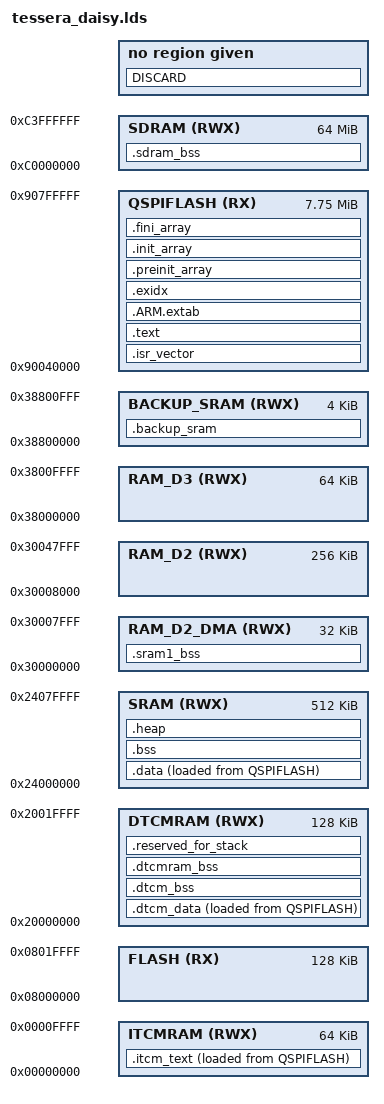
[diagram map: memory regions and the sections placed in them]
/* SPDX-License-Identifier: MIT (libDaisy, LICENSES/MIT-libDaisy.txt); Tessera's placements: Copyright (C) 2026 Theo Dainis */
/* Andamento: the Daisy Seed's memory map for Tessera, BOOT_QSPI.
 *
 * libDaisy's core/STM32H750IB_qspi.lds (libDaisy 1289a00, MIT; its own header follows), with Tessera's audio path
 * placed in the H750's fast memories. Everything else is as libDaisy has it: code in the 8 MB QSPI flash (read
 * through the cache), data in the 512 KB AXI SRAM, DMA buffers in RAM_D2_DMA (not cached), the stack at the top
 * of DTCM.
 *
 *   ITCM  64 KB  .itcm_text  the code that runs for every sample: what the FM-1 build keeps in its RAM
 *                            (.audio_text, .dsp_text), the mixer and the engines' render loops, as many as fit
 *                            (itcm_pick.py chooses, at build time). No wait states and no cache misses, where
 *                            QSPI code can stall on a miss.
 *   DTCM 128 KB  .dtcm_data  the tables those read for every sample (.dsp_tables and the hot const tables)
 *                .dtcm_bss   the state they write: tracks, effects, FM6's RAM tables, the mix batch, the first
 *                            banks of the audio arena (resources.c), .audio_scratch. The stack shares DTCM, from
 *                            the top down: DTCM_STACK is kept free for it.
 *   AXI SRAM     .bss        as libDaisy, plus the FM-1's .pool (effect lines, big buffers) and .noinit (zeroed:
 *                            nothing is kept across a reset on the Daisy yet)
 *   SDRAM 64 MB  .sdram_bss  nothing of Tessera's yet: long buffers (Beads, samples) go there (DSY_SDRAM_BSS).
 *                            Cached, so a DMA into it needs cache maintenance.
 *
 * ITCM and DTCM are filled by tessera_memory_init (main.cpp) before anything else runs: libDaisy's startup only
 * copies .data and zeroes .bss. Calls between ITCM (0x00000000) and QSPI (0x90000000) are too far for one branch
 * instruction: the linker adds a small veneer for each, which costs a few cycles a call.
 * Names are matched as -fdata-sections spells them (.rodata.NAME, .bss.NAME): a renamed table or array simply
 * stays in the AXI SRAM or QSPI, slower but correct. memcheck.py, run after the link, says where the hot ones are. */

/* Generated by LinkerScriptGenerator [http://visualgdb.com/tools/LinkerScriptGenerator]
 * Target: STM32H750IB
 * The file is provided under the BSD license.
 * yeah okay but i also modified it a lot so like, give me some credit too mr BSD
 */

ENTRY(Reset_Handler)

MEMORY
{
	FLASH       (RX)  : ORIGIN = 0x08000000, LENGTH = 128K
	DTCMRAM     (RWX) : ORIGIN = 0x20000000, LENGTH = 128K
	SRAM        (RWX) : ORIGIN = 0x24000000, LENGTH = 512K
	RAM_D2_DMA  (RWX) : ORIGIN = 0x30000000, LENGTH = 32K
	RAM_D2      (RWX) : ORIGIN = 0x30008000, LENGTH = 256K
	RAM_D3      (RWX) : ORIGIN = 0x38000000, LENGTH = 64K
	BACKUP_SRAM (RWX) : ORIGIN = 0x38800000, LENGTH = 4K
	ITCMRAM     (RWX) : ORIGIN = 0x00000000, LENGTH = 64K
	SDRAM       (RWX) : ORIGIN = 0xc0000000, LENGTH = 64M
	QSPIFLASH   (RX)  : ORIGIN = 0x90040000, LENGTH = 7936K
}

_estack = 0x20020000;
DTCM_STACK = 32K;                       /* kept free at the top of DTCM for the stack (main and interrupts) */

SECTIONS
{
	.isr_vector :
	{
		. = ALIGN(4);
		KEEP(*(.isr_vector))
		. = ALIGN(4);
	} > QSPIFLASH

	/* Tessera's audio path in ITCM, loaded from QSPI and copied at boot. Before .text, whose *(.text*) would
	 * otherwise take these first (the linker places a section by the first rule that matches it) */
	.itcm_text :
	{
		. = ALIGN(8);
		_sitcm_text = .;
		INCLUDE itcm.ld                 /* made at build time by itcm_pick.py: .audio_text, .dsp_text, then the hot functions while they fit */
		. = ALIGN(8);
		_eitcm_text = .;
	} > ITCMRAM AT > QSPIFLASH
	_litcm_text = LOADADDR(.itcm_text);

	/* the tables the audio path reads, copied to DTCM at boot */
	.dtcm_data :
	{
		. = ALIGN(8);
		_sdtcm_data = .;
		*(.dsp_tables*)
		*(.data.tables*)                /* TABLE_RAM (gen_tables.py): the FM-1 keeps these in RAM for the same reason */
		*tessera_core.o(.rodata.SINE .rodata.PITCH_OCT .rodata.ENV_LIN .rodata.LFO_INC .rodata.MICRO_SCALE)
		*tessera_core.o(.rodata.FM6_FREQ_RES .rodata.FM6_MKI_* .rodata.FM6_OPL_* .rodata.FM6_DETUNE .rodata.FM6_FINE)
		*tessera_core.o(.rodata.FM6_GLISS .rodata.FM6_PORTA .rodata.FM6_LFO_INC)
		*tessera_core.o(.rodata.OR_AMOUNT .rodata.OR_ENV_* .rodata.OR_LFO_INC)
		. = ALIGN(8);
		_edtcm_data = .;
	} > DTCMRAM AT > QSPIFLASH
	_ldtcm_data = LOADADDR(.dtcm_data);

	/* the state the audio path writes, zeroed at boot */
	.dtcm_bss (NOLOAD) :
	{
		. = ALIGN(32);
		_sdtcm_bss = .;
		*(.audio_scratch*)
		*tessera_core.o(.bss.trk .bss.fx_state .bss.fx_send_extra_* .bss.batch_*)
		*tessera_core.o(.bss.FM6_SIN .bss.FM6_MKI_LOG .bss.FM6_MKI_EXP .bss.fm6_*)
		*tessera_core.o(.bss.resource_host_low .bss.resource_host_data .bss.resource_host_retained)
		. = ALIGN(8);
		_edtcm_bss = .;
	} > DTCMRAM

	.text :
	{
		. = ALIGN(4);
		_stext = .;

		*(.text)
		*(.text*)
		*(.rodata)
		*(.rodata*)
		*(.glue_7)
		*(.glue_7t)
		KEEP(*(.init))
		KEEP(*(.fini))
		. = ALIGN(4);
		_etext = .;

	} > QSPIFLASH

	.ARM.extab :
	{
		. = ALIGN(4);
		*(.ARM.extab)
		*(.gnu.linkonce.armextab.*)
		. = ALIGN(4);
	} > QSPIFLASH

	.exidx :
	{
		. = ALIGN(4);
		PROVIDE(__exidx_start = .);
		*(.ARM.exidx*)
		. = ALIGN(4);
		PROVIDE(__exidx_end = .);
	} > QSPIFLASH

	.ARM.attributes 0 : { *(.ARM.attributes) }

	.preinit_array :
	{
		PROVIDE_HIDDEN(__preinit_array_start = .);
		KEEP(*(.preinit_array*))
		PROVIDE_HIDDEN(__preinit_array_end = .);
	} > QSPIFLASH

	.init_array :
	{
		PROVIDE_HIDDEN(__init_array_start = .);
		KEEP(*(SORT(.init_array.*)))
		KEEP(*(.init_array*))
		PROVIDE_HIDDEN(__init_array_end = .);
	} > QSPIFLASH

	.fini_array :
	{
		PROVIDE_HIDDEN(__fini_array_start = .);
		KEEP(*(.fini_array*))
		KEEP(*(SORT(.fini_array.*)))
		PROVIDE_HIDDEN(__fini_array_end = .);
	} > QSPIFLASH

	.sram1_bss (NOLOAD) :
	{
		. = ALIGN(4);
		_ssram1_bss = .;

		PROVIDE(__sram1_bss_start__ = _sram1_bss);
		*(.sram1_bss)
		*(.sram1_bss*)
		. = ALIGN(4);
		_esram1_bss = .;

		PROVIDE(__sram1_bss_end__ = _esram1_bss);
	} > RAM_D2_DMA

	.data :
	{
		. = ALIGN(4);
		_sdata = .;

		PROVIDE(__data_start__ = _sdata);
		*(.data)
		*(.data*)
		. = ALIGN(4);
		_edata = .;

		PROVIDE(__data_end__ = _edata);
	} > SRAM AT > QSPIFLASH

	_sidata = LOADADDR(.data);

	.bss (NOLOAD) :
	{
		. = ALIGN(4);
		_sbss = .;

		PROVIDE(__bss_start__ = _sbss);
		*(.bss)
		*(.bss*)
		*(COMMON)
		*(.pool*)
		*(.noinit*)
		. = ALIGN(4);
		_ebss = .;

		PROVIDE(__bss_end__ = _ebss);
	} > SRAM

	.dtcmram_bss (NOLOAD) :
	{
		. = ALIGN(4);
		_sdtcmram_bss = .;

		PROVIDE(__dtcmram_bss_start__ = _sdtcmram_bss);
		*(.dtcmram_bss)
		*(.dtcmram_bss*)
		. = ALIGN(4);
		_edtcmram_bss = .;

		PROVIDE(__dtcmram_bss_end__ = _edtcmram_bss);
	} > DTCMRAM
	ASSERT(_edtcmram_bss <= _estack - DTCM_STACK, "DTCM: the data leaves less than DTCM_STACK for the stack")

	/*
	.sdram_text :
	{
		. = ALIGN(4);
		_ssdram_text = .;

		PROVIDE(__sdram_text_start = _ssdram_text);
		*(.sdram_text)
		*(.sdram_text*)
		. = ALIGN(4);
		_esdram_text = .;

		PROVIDE(__sdram_text_end = _esdram_text);
	} > SDRAM AT >FLASH
	_sisdram_text = LOADADDR(.sdram_text);
	*/

	.sdram_bss (NOLOAD) :
	{
		. = ALIGN(4);
		_ssdram_bss = .;

		PROVIDE(__sdram_bss_start = _ssdram_bss);
		*(.sdram_bss)
		*(.sdram_bss*)
		. = ALIGN(4);
		_esdram_bss = .;

		PROVIDE(__sdram_bss_end = _esdram_bss);
	} > SDRAM

	.backup_sram (NOLOAD) :
	{
		. = ALIGN(4);
		_sbackup_sram = .;

		PROVIDE(__backup_sram_start = _sbackup_sram);
		*(.backup_sram)
		*(.backup_sram*)
		. = ALIGN(4);
		_ebackup_sram = .;

		PROVIDE(__backup_sram_end = _ebackup_sram);
	} > BACKUP_SRAM


    /* .qspiflash_text :
	{
		. = ALIGN(4);
		_sqspiflash_text = .;

		PROVIDE(__qspiflash_text_start = _sqspiflash_text);
		*(.qspiflash_text)
		*(.qspiflash_text*)
		. = ALIGN(4);
		_eqspiflash_text = .;

		PROVIDE(__qspiflash_text_end = _eqspiflash_text);
	} > QSPIFLASH

	.qspiflash_data :
	{
		. = ALIGN(4);
		_sqspiflash_data = .;

		PROVIDE(__qspiflash_data_start = _sqspiflash_data);
		*(.qspiflash_data)
		*(.qspiflash_data*)
		. = ALIGN(4);
		_eqspiflash_data = .;

		PROVIDE(__qspiflash_data_end = _eqspiflash_data);
	} > QSPIFLASH

	.qspiflash_bss (NOLOAD) :
	{
		. = ALIGN(4);
		_sqspiflash_bss = .;

		PROVIDE(__qspiflash_bss_start = _sqspiflash_bss);
		*(.qspiflash_bss)
		*(.qspiflash_bss*)
		. = ALIGN(4);
		_eqspiflash_bss = .;

		PROVIDE(__qspiflash_bss_end = _eqspiflash_bss);
	} > QSPIFLASH */

	.heap (NOLOAD) :
	{
		. = ALIGN(4);
		PROVIDE(__heap_start__ = .);
		PROVIDE(__heap_start = .);
		KEEP(*(.heap))
		. = ALIGN(4);
		PROVIDE(__heap_end = .);
		PROVIDE(__heap_end__ = .);
	} > SRAM

	PROVIDE(end = .);

	.reserved_for_stack (NOLOAD) :
	{
		. = ALIGN(4);
		PROVIDE(__reserved_for_stack_start__ = .);
		KEEP(*(.reserved_for_stack))
		. = ALIGN(4);
		PROVIDE(__reserved_for_stack_end__ = .);
	} > DTCMRAM

    DISCARD :
    {
        libc.a ( * )
        libm.a ( * )
        libgcc.a ( * )
    }

}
